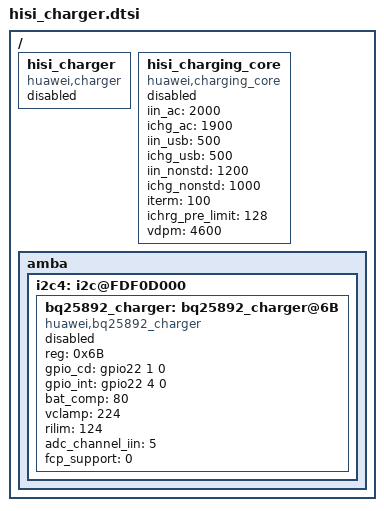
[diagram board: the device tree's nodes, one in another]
/ {
	hisi_charger: hisi_charger{
		compatible = "huawei,charger";
		status = "disabled";
	};
	hisi_charging_core:hisi_charging_core{
		compatible = "huawei,charging_core";
		iin_ac = <2000>;
		ichg_ac = <1900>;
		iin_usb = <500>;
		ichg_usb = <500>;
		iin_nonstd = <1200>;
		ichg_nonstd = <1000>;
		iterm = <100>;
		ichrg_pre_limit = <128>;
		vdpm = <4600>;
		status = "disabled";
	};
	amba {
		i2c4: i2c@FDF0D000 {
			bq25892_charger: bq25892_charger@6B{
                 		compatible = "huawei,bq25892_charger";
                 		reg = <0x6B>;
                 		gpio_cd = <&gpio22 1 0>;
                 		gpio_int = <&gpio22 4 0>;
                 		bat_comp = <80>;
                 		vclamp = <224>;
                 		rilim = <124>;
				adc_channel_iin = <5>;
                 		fcp_support = <0>;
                 		status = "disabled";
			};
		};
	};
};
